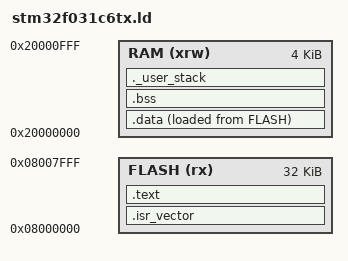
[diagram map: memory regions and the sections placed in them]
/*
 * STM32F031C6Tx linker script
 * Flash: 32 KB at 0x08000000
 * RAM:    4 KB at 0x20000000
 */

ENTRY(Reset_Handler)

MEMORY
{
    FLASH (rx)  : ORIGIN = 0x08000000, LENGTH = 32K
    RAM   (xrw) : ORIGIN = 0x20000000, LENGTH = 4K
}

_estack = ORIGIN(RAM) + LENGTH(RAM);

SECTIONS
{
    .isr_vector :
    {
        . = ALIGN(4);
        KEEP(*(.isr_vector))
        . = ALIGN(4);
    } > FLASH

    .text :
    {
        . = ALIGN(4);
        *(.text*)
        *(.rodata*)
        . = ALIGN(4);
        _etext = .;
    } > FLASH

    _sidata = LOADADDR(.data);

    .data :
    {
        . = ALIGN(4);
        _sdata = .;
        *(.data*)
        . = ALIGN(4);
        _edata = .;
    } > RAM AT > FLASH

    .bss :
    {
        . = ALIGN(4);
        _sbss = .;
        *(.bss*)
        *(COMMON)
        . = ALIGN(4);
        _ebss = .;
    } > RAM

    ._user_stack :
    {
        . = ALIGN(8);
        . = . + 0x400;
        . = ALIGN(8);
    } > RAM
}
